VERSION "TunerOS synthetic simulation CAN database 1.0"

NS_ :

BS_:

BU_: TunerOsSimulatedDme

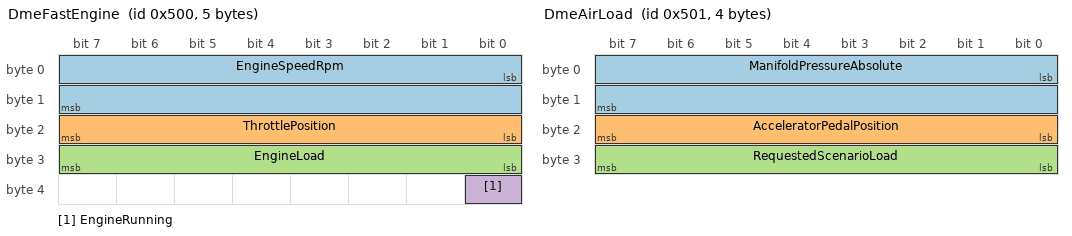
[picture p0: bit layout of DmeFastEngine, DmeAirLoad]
BO_ 1280 DmeFastEngine: 5 TunerOsSimulatedDme
 SG_ EngineSpeedRpm : 0|16@1+ (0.25,0) [0|16383.75] "rpm" Vector__XXX
 SG_ ThrottlePosition : 16|8@1+ (0.00392156862745098,0) [0|1] "normalized" Vector__XXX
 SG_ EngineLoad : 24|8@1+ (0.00392156862745098,0) [0|1] "normalized" Vector__XXX
 SG_ EngineRunning : 32|1@1+ (1,0) [0|1] "boolean" Vector__XXX

BO_ 1281 DmeAirLoad: 4 TunerOsSimulatedDme
 SG_ ManifoldPressureAbsolute : 0|16@1+ (0.1,0) [0|6553.5] "kPa_abs" Vector__XXX
 SG_ AcceleratorPedalPosition : 16|8@1+ (0.00392156862745098,0) [0|1] "normalized" Vector__XXX
 SG_ RequestedScenarioLoad : 24|8@1+ (0.00392156862745098,0) [0|1] "normalized" Vector__XXX

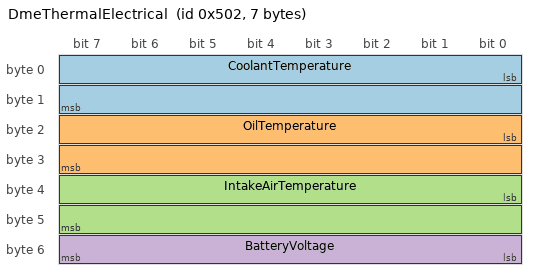
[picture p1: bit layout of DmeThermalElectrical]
BO_ 1282 DmeThermalElectrical: 7 TunerOsSimulatedDme
 SG_ CoolantTemperature : 0|16@1+ (0.1,-100) [-100|6453.5] "degC" Vector__XXX
 SG_ OilTemperature : 16|16@1+ (0.1,-100) [-100|6453.5] "degC" Vector__XXX
 SG_ IntakeAirTemperature : 32|16@1+ (0.1,-100) [-100|6453.5] "degC" Vector__XXX
 SG_ BatteryVoltage : 48|8@1+ (0.1,0) [0|25.5] "V" Vector__XXX

CM_ "TunerOS synthetic simulation CAN database. Not BMW, E90, N54, PT-CAN, captured, or reverse-engineered OEM data.";
CM_ BU_ TunerOsSimulatedDme "TunerOS simulated DME publisher; not BMW firmware.";
CM_ BO_ 1280 "Synthetic 100 Hz fast-engine publication.";
CM_ BO_ 1281 "Synthetic 50 Hz air/load publication.";
CM_ BO_ 1282 "Synthetic 10 Hz thermal/electrical publication.";

BA_DEF_ BO_ "GenMsgCycleTime" INT 0 65535;
BA_DEF_DEF_ "GenMsgCycleTime" 0;
BA_ "GenMsgCycleTime" BO_ 1280 10;
BA_ "GenMsgCycleTime" BO_ 1281 20;
BA_ "GenMsgCycleTime" BO_ 1282 100;
